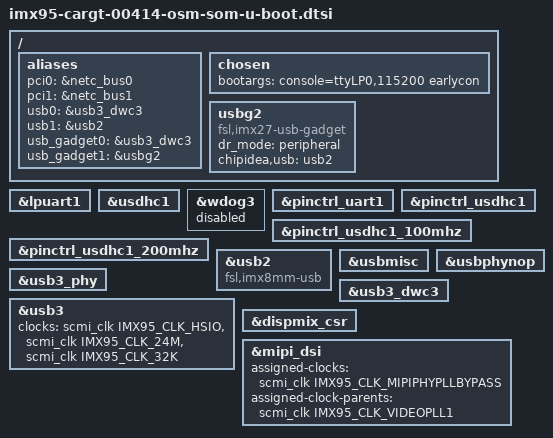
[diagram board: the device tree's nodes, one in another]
// SPDX-License-Identifier: GPL-2.0+
/*
 * Copyright 2025 NXP
 * Copyright 2026 Cargt
 *
 * U-Boot additions for the Cargt i.MX 95 00414 OSM-L SOM, following
 * imx95-19x19-evk-u-boot.dtsi. Carrier -u-boot.dtsi files include this.
 */

#include "imx95-u-boot.dtsi"

/ {
	aliases {
		pci0 = &netc_bus0;
		pci1 = &netc_bus1;
		usb0 = &usb3_dwc3;
		usb1 = &usb2;
		usb_gadget0 = &usb3_dwc3;
		usb_gadget1 = &usbg2;
	};

	chosen {
		bootargs = "console=ttyLP0,115200 earlycon";
	};

	usbg2: usbg2 {
		compatible = "fsl,imx27-usb-gadget";
		dr_mode = "peripheral";
		chipidea,usb = <&usb2>;
		bootph-pre-ram;
		status = "okay";
	};
};

&lpuart1 {
	bootph-pre-ram;
};

&usdhc1 {
	bootph-pre-ram;
};

&wdog3 {
	status = "disabled";
};

&pinctrl_uart1 {
	bootph-pre-ram;
};

&pinctrl_usdhc1 {
	bootph-pre-ram;
};

&pinctrl_usdhc1_100mhz {
	bootph-pre-ram;
};

&pinctrl_usdhc1_200mhz {
	bootph-pre-ram;
};

/* USB serial-download / fastboot (UUU) paths, as on the EVK */
&usb2 {
	compatible = "fsl,imx8mm-usb", "fsl,imx7d-usb";
	/delete-property/power-domains;
	bootph-pre-ram;
};

&usbmisc {
	bootph-pre-ram;
};

&usbphynop {
	bootph-pre-ram;
};

&usb3_phy {
	bootph-pre-ram;
};

&usb3 {
	clocks = <&scmi_clk IMX95_CLK_HSIO>,
		 <&scmi_clk IMX95_CLK_24M>,
		 <&scmi_clk IMX95_CLK_32K>;
	clock-names = "hsio", "ref", "suspend";

	/delete-property/power-domains;
	bootph-pre-ram;
};

&usb3_dwc3 {
	bootph-pre-ram;
};

&dispmix_csr {
	/delete-property/ assigned-clocks;
	/delete-property/ assigned-clock-rates;
	/delete-property/ assigned-clock-parents;
};

&mipi_dsi {
	assigned-clocks = <&scmi_clk IMX95_CLK_MIPIPHYPLLBYPASS>;
	assigned-clock-parents = <&scmi_clk IMX95_CLK_VIDEOPLL1>;
};
